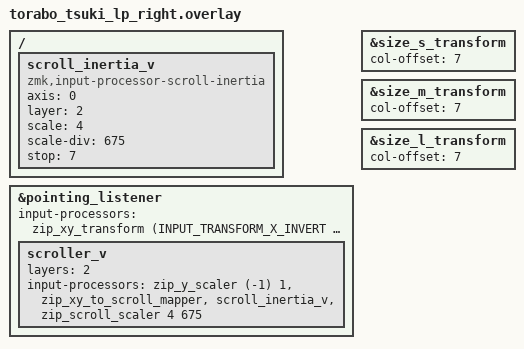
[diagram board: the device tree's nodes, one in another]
#include "torabo_tsuki_lp.dtsi"
#include <input/processors.dtsi>
#include <dt-bindings/zmk/input_transform.h>

/ {
    scroll_inertia_v: scroll_inertia_v {
        compatible = "zmk,input-processor-scroll-inertia";
        #input-processor-cells = <0>;
        axis = <0>;          /* 2Dスクロール */
        layer = <2>;         /* scroll レイヤーと一致 */
        scale = <4>;         /* zip_scroll_scaler と同じ */
        scale-div = <675>;
        stop = <7>;          /* サイト推奨の終了閾値 */
    };
}

&pointing_listener {
    input-processors = <&zip_xy_transform (INPUT_TRANSFORM_X_INVERT | INPUT_TRANSFORM_Y_INVERT)>;

    scroller_v {
        layers = <2>;
        input-processors = <
            &zip_y_scaler (-1) 1
            &zip_xy_to_scroll_mapper
            &scroll_inertia_v
            &zip_scroll_scaler 4 675
        >;
    };
};



&size_s_transform {
    col-offset = <7>;
};

&size_m_transform {
    col-offset = <7>;
};

&size_l_transform {
    col-offset = <7>;
};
